VERSION ""

NS_ :

BS_:

BU_: JETSON VCU ACU RES DYN_F DYN_R FSG_DATA_LOGGER

BO_ 3221225472 VECTOR__INDEPENDENT_SIG_MSG: 0 Vector__XXX
 SG_ EBS_Pressure_Rear : 32|8@1+ (10,0) [0|150] "bar" Vector__XXX
 SG_ EBS_Pressure_Front : 24|8@1+ (10,0) [0|150] "bar" Vector__XXX
 SG_ NewSignal_0005 : 0|8@1+ (1,0) [0|0] "" Vector__XXX
 SG_ NewSignal_0015 : 32|8@1+ (1,0) [0|0] "" Vector__XXX

BO_ 81 ACU_MS: 1 ACU
 SG_ Mission_Select : 0|8@1+ (1,0) [0|0] ""  JETSON

BO_ 97 JETSON_MS: 1 JETSON
 SG_ Mission_Select : 0|8@1+ (1,0) [0|0] ""  ACU

BO_ 1296 VCU_RPM: 2 VCU
 SG_ RPM : 0|16@1- (1,0) [0|6000] "RPM"  JETSON

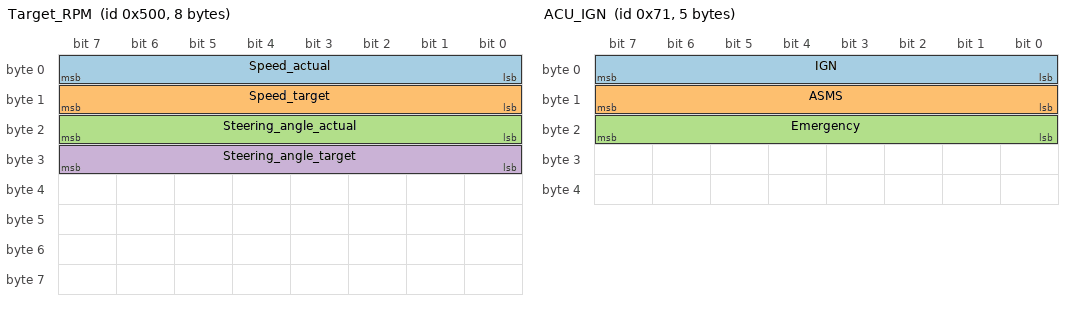
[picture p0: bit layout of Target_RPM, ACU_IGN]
BO_ 1280 Target_RPM: 8 ACU
 SG_ Speed_actual : 0|8@1+ (0.5,0) [0|0] "Km/h"  VCU
 SG_ Speed_target : 8|8@1+ (0.5,0) [0|0] "Km/h" Vector__XXX
 SG_ Steering_angle_actual : 16|8@1- (0.5,0) [0|0] "º" Vector__XXX
 SG_ Steering_angle_target : 24|8@1- (0.5,0) [0|0] "º" Vector__XXX

BO_ 113 ACU_IGN: 5 ACU
 SG_ IGN : 0|8@1+ (1,0) [0|1] ""  VCU
 SG_ ASMS : 8|8@1+ (1,0) [0|1] ""  VCU
 SG_ Emergency : 16|8@1+ (1,0) [0|0] ""  VCU

BO_ 1298 RD_JETSON: 1 ACU
 SG_ RD : 0|8@1+ (1,0) [0|0] ""  JETSON

BO_ 1282 AS_STATE: 1 JETSON
 SG_ STATE : 0|8@1+ (1,0) [0|0] ""  VCU,ACU

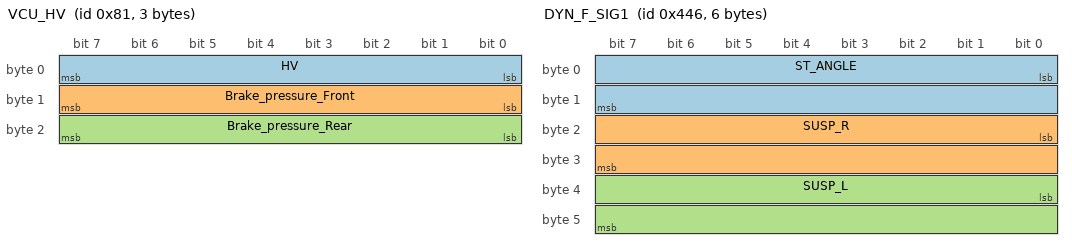
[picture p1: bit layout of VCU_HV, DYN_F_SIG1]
BO_ 129 VCU_HV: 3 VCU
 SG_ HV : 0|8@1+ (1,0) [0|0] ""  ACU
 SG_ Brake_pressure_Front : 8|8@1+ (1,0) [0|0] "" Vector__XXX
 SG_ Brake_pressure_Rear : 16|8@1+ (1,0) [0|0] "" Vector__XXX

BO_ 401 RES: 8 RES
 SG_ SIGNAL : 0|8@1+ (1,0) [0|0] ""  JETSON,ACU

BO_ 1094 DYN_F_SIG1: 6 DYN_F
 SG_ ST_ANGLE : 0|16@1- (0.1,0) [0|0] "º" Vector__XXX
 SG_ SUSP_R : 16|16@1+ (0.1,0) [0|0] "mm" Vector__XXX
 SG_ SUSP_L : 32|16@1+ (0.1,0) [0|0] "mm" Vector__XXX

BO_ 1110 DYN_F_SIG2: 4 DYN_F
 SG_ SPD_LEFT : 0|16@1+ (0.1,0) [0|0] "km/h" Vector__XXX
 SG_ SPD_RIGHT : 16|16@1+ (0.1,0) [0|0] "km/h" Vector__XXX

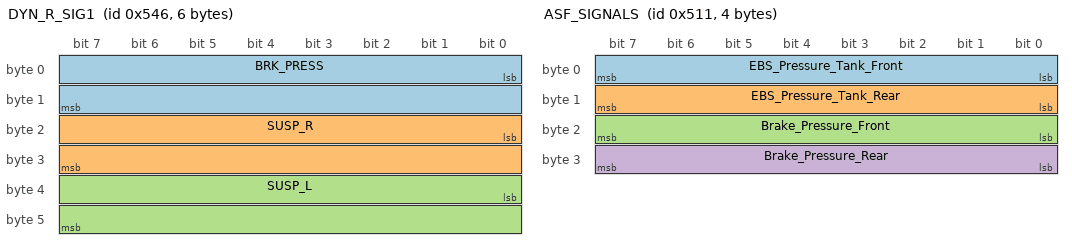
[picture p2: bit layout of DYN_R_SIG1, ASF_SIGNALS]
BO_ 1350 DYN_R_SIG1: 6 DYN_R
 SG_ BRK_PRESS : 0|16@1+ (0.1,0) [0|0] "bar" Vector__XXX
 SG_ SUSP_R : 16|16@1+ (0.1,0) [0|0] "mm" Vector__XXX
 SG_ SUSP_L : 32|16@1+ (0.1,0) [0|0] "mm" Vector__XXX

BO_ 1366 DYN_R_SIG2: 4 DYN_R
 SG_ SPD_LEFT : 0|16@1+ (0.1,0) [0|0] "km/h" Vector__XXX
 SG_ SPD_RIGHT : 16|16@1+ (0.1,0) [0|0] "km/h" Vector__XXX

BO_ 1297 ASF_SIGNALS: 4 ACU
 SG_ EBS_Pressure_Tank_Front : 0|8@1+ (10,0) [0|0] "bar" Vector__XXX
 SG_ EBS_Pressure_Tank_Rear : 8|8@1+ (10,0) [0|0] "bar" Vector__XXX
 SG_ Brake_Pressure_Front : 16|8@1+ (10,0) [0|0] "bar" Vector__XXX
 SG_ Brake_Pressure_Rear : 24|8@1+ (10,0) [0|0] "bar" Vector__XXX

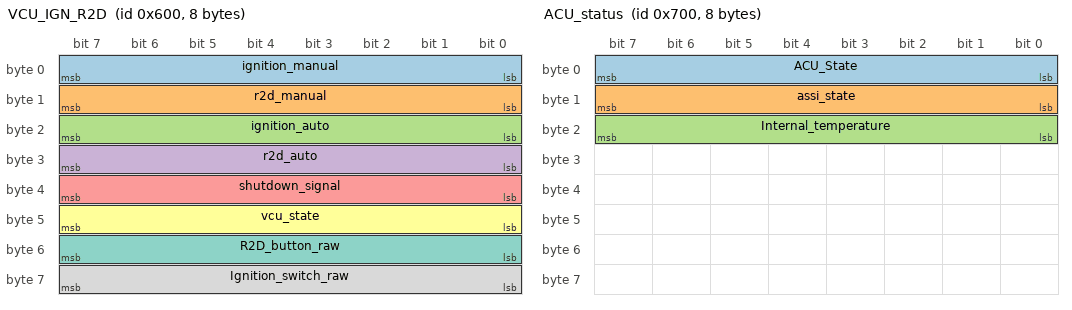
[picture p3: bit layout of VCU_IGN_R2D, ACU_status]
BO_ 1536 VCU_IGN_R2D: 8 VCU
 SG_ ignition_manual : 0|8@1+ (1,0) [0|0] "" Vector__XXX
 SG_ r2d_manual : 8|8@1+ (1,0) [0|0] "" Vector__XXX
 SG_ ignition_auto : 16|8@1+ (1,0) [0|0] "" Vector__XXX
 SG_ r2d_auto : 24|8@1+ (1,0) [0|0] "" Vector__XXX
 SG_ shutdown_signal : 32|8@1+ (1,0) [0|0] "" Vector__XXX
 SG_ vcu_state : 40|8@1+ (1,0) [0|0] "" Vector__XXX
 SG_ R2D_button_raw : 48|8@1+ (1,0) [0|0] "" Vector__XXX
 SG_ Ignition_switch_raw : 56|8@1+ (1,0) [0|0] "" Vector__XXX

BO_ 1792 ACU_status: 8 ACU
 SG_ ACU_State : 0|8@1+ (1,0) [0|0] "" Vector__XXX
 SG_ assi_state : 8|8@1+ (1,0) [0|0] "" Vector__XXX
 SG_ Internal_temperature : 16|8@1+ (1,0) [0|0] "º" Vector__XXX

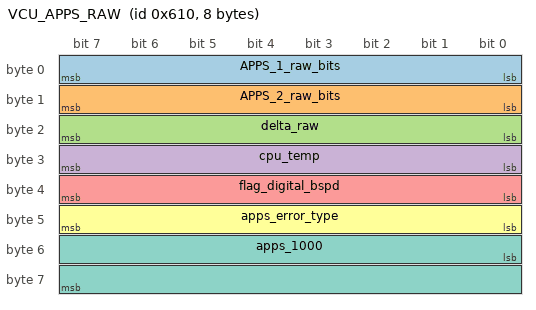
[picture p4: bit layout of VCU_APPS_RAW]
BO_ 1552 VCU_APPS_RAW: 8 VCU
 SG_ APPS_1_raw_bits : 0|8@1+ (1,0) [0|0] "" Vector__XXX
 SG_ APPS_2_raw_bits : 8|8@1+ (1,0) [0|0] "" Vector__XXX
 SG_ delta_raw : 16|8@1+ (1,0) [0|0] "" Vector__XXX
 SG_ cpu_temp : 24|8@1+ (1,0) [0|0] "" Vector__XXX
 SG_ flag_digital_bspd : 32|8@1+ (1,0) [0|0] "" Vector__XXX
 SG_ apps_error_type : 40|8@1+ (1,0) [0|0] "" Vector__XXX
 SG_ apps_1000 : 48|16@1+ (1,0) [0|0] "" Vector__XXX

CM_ SG_ 3221225472 EBS_Pressure_Rear "(null)";
CM_ SG_ 3221225472 EBS_Pressure_Front "Perdu gay";
CM_ SG_ 1282 STATE "Regulations";
VAL_ 81 Mission_Select 0 "Manual" 1 "Acceleration" 2 "Skidpad" 3 "Trackdrive" 4 "Braketest" 5 "Inspection" 6 "Autocross" ;
VAL_ 97 Mission_Select 0 "Manual" 1 "Acceleration" 2 "Skidpadd" 3 "Trackdrive" 4 "Braketest" 5 "Inspection" 6 "Autocross" ;
VAL_ 113 IGN 0 "OFF" 1 "ON" ;
VAL_ 113 ASMS 0 "OFF" 1 "ON" ;
VAL_ 113 Emergency 1 "Emergency_ON" 0 "Emergency_OFF" ;
VAL_ 1298 RD 0 "OFF" 1 "ON" ;
VAL_ 1282 STATE 1 "OFF" 2 "Ready" 3 "Driving" 4 "Emergency" 5 "Finish" ;
VAL_ 129 HV 0 "hv off" 9 "hv on" 10 "contactor error" ;
VAL_ 401 SIGNAL 5 "GO_SIGNAL" 7 "GO_SIGNAL_2" 0 "EMERGENCY" ;
VAL_ 1536 vcu_state 1 "INIT" 2 "SHUTDOWN" 3 "STANDBY" 4 "PRECHARGE" 5 "WAIT_R2D_MANUAL" 6 "WAIT_R2D_AUTO" 7 "READY_MANUAL" 8 "READY_AUTO" 9 "EMERGENCY" ;
VAL_ 1792 ACU_State 0 "INIT" 1 "MS" 2 "JETSON_WAITING" 3 "IBIT_SEQ" 4 "READY" 5 "DRIVING" 6 "EBS_EROR" 7 "EMERGENCY" 8 "FINISHED" 9 "MANUAL" ;
